# H616 register map
Vendor: Allwinner; Series: H616; File version: 0.1
CPU: other 0, little endian, MPU, no FPU, 0 interrupt priority bits
Registers are 32-bit, read-write, reset 0x0 unless marked. A register's access mark holds for its fields unless they carry their own. Offsets are from the block's base; [hi:lo] are bit positions; lines under a group give offsets from that group; {n}, {i} and the like mark numbered series; 'fields as' and 'values as' point back to an identical list.

## PWM
Base 0x0300A000
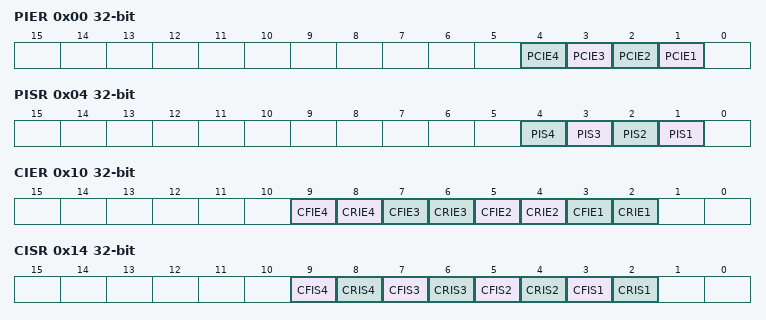
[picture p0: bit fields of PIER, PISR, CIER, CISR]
0x00 PIER — PWM IRQ Enable Register
  [n] PCIE{n} (n=1..4) — PWM Channel {n} Interrupt Enable 0: PWM channel {n} interrupt disable 1: PWM channel {n} interrupt enable
    0=PWM_channel_{n}_interrupt_disable; 1=PWM_channel_{n}_interrupt_enable
0x04 PISR — PWM IRQ Status Register
  [n] PIS{n} write-1-clears (n=1..4) — PWM Channel {n} Interrupt Status When PWM channel {n} counter reaches Entire Cycle Value, this bit is set 1 by hardware. Writing 1 to clear this bit. Reads 0: PWM channel {n} interrupt is not pending. Reads 1: PWM channel {n} interrupt is pending. Writes 0: No effect. Writes 1: Clear PWM channel {n} interrupt status.
0x10 CIER — Capture IRQ Enable Register
  [9] CFIE4 — If the bit is set 1, when capturing channel 4 captures falling edge, it generates a capturing channel 4 pending. 0: Capture channel 4 fall lock interrupt disable 1: Capture channel 4 fall lock interrupt enable
    0=Capture_channel_4_fall_lock_interrupt_disable; 1=Capture_channel_4_fall_lock_interrupt_enable
  [2n] CRIE{n} (n=1..4) — If the bit is set 1, when capturing channel {n} captures rising edge, it generates a capturing channel {n} pending. 0: Capturing channel {n} rise lock interrupt disable 1: Capturing channel {n} rise lock interrupt enable
    0=Capturing_channel_{n}_rise_lock_interrupt_disable; 1=Capturing_channel_{n}_rise_lock_interrupt_enable
  [7] CFIE3 — If the bit is set 1, when capturing channel 3 captures falling edge, it generates a capturing channel 3 pending. 0: Capturing channel 3 fall lock interrupt disable 1: Capturing channel 3 fall lock interrupt enable
    0=Capturing_channel_3_fall_lock_interrupt_disable; 1=Capturing_channel_3_fall_lock_interrupt_enable
  [5] CFIE2 — If the bit is set 1, when capturing channel 2 captures falling edge, it generates a capturing channel 2 pending. 0: Capturing channel 2 fall lock interrupt disable 1: Capturing channel 2 fall lock interrupt enable
    0=Capturing_channel_2_fall_lock_interrupt_disable; 1=Capturing_channel_2_fall_lock_interrupt_enable
  [3] CFIE1 — If the bit is set 1, when capturing channel 1 captures falling edge, it generates a capturing channel 1 pending. 0: Capturing channel 1 fall lock interrupt disable 1: Capturing channel 1 fall lock interrupt enable
    0=Capturing_channel_1_fall_lock_interrupt_disable; 1=Capturing_channel_1_fall_lock_interrupt_enable
0x14 CISR — Capture IRQ Status Register
  [9] CFIS4 write-1-clears — Capturing channel 4 falling lock interrupt status. When capturing channel 4 captures falling edge, if capturing channel 4 fall lock interrupt ( CFIE4 ) is enabled, this bit is set 1 by hardware.Writing 1 to clear this bit. Reads 0: Capturing channel 4 interrupt is not pending. Reads 1: Capturing channel 4 interrupt is pending. Writes 0: No effect. Writes 1: Clear capturing channel 4 interrupt status.
  [8] CRIS4 write-1-clears — Capturing channel 4 rising lock interrupt status. When capturing channel 4 captures rising edge, if capturing channel 4 rise lock interrupt ( CRIE4 ) is enabled, this bit is set 1 by hardware. Writing 1 to clear this bit. Reads 0: Capturing channel 4 interrupt is not pending. Reads 1: Capturing channel 4 interrupt is pending. Writes 0: No effect. Writes 1: Clear capturing channel 4 interrupt status.
  [7] CFIS3 write-1-clears — Capture channel 3 falling lock interrupt status. When capture channel 3 captures falling edge, if capture channel 3 fall lock interrupt ( CFIE3 ) is enabled, this bit is set 1 by hardware.Writing 1 to clear this bit. Reads 0: Capture channel 3 interrupt is not pending. Reads 1: Capture channel 3 interrupt is pending. Writes 0: no effect. Writes 1: Clear capture channel 3 interrupt status.
  [6] CRIS3 write-1-clears — Capture channel 3 rising lock interrupt status. When capture channel 3 captures rising edge, if capture channel 3 rise lock interrupt ( CRIE3 ) is enabled, this bit is set 1 by hardware. Writing 1 to clear this bit. Reads 0: Capture channel 3 interrupt is not pending. Reads 1: Capture channel 3 interrupt is pending. Writes 0: no effect. Writes 1: Clear capture channel 3 interrupt status.
  [5] CFIS2 write-1-clears — Capture channel 2 falling lock interrupt status. When capture channel 2 captures falling edge, if capture channel 2 fall lock interrupt ( CFIE2 ) is enabled, this bit is set 1 by hardware.Writing 1 to clear this bit. Reads 0: Capture channel 2 interrupt is not pending. Reads 1: Capture channel 2 interrupt is pending. Writes 0: no effect. Writes 1: Clear capture channel 2 interrupt status.
  [4] CRIS2 write-1-clears — Capture channel 2 rising lock interrupt status. When capture channel 2 captures rising edge, if capture channel 2 rise lock interrupt ( CRIE2 ) is enabled, this bit is set 1 by hardware. Writing 1 to clear this bit. Reads 0: Capture channel 2 interrupt is not pending. Reads 1: Capture channel 2 interrupt is pending. Writes 0: no effect. Writes 1: Clear capture channel 2 interrupt status.
  [3] CFIS1 write-1-clears — Capture channel 1 falling lock interrupt status. When capture channel 1 captures falling edge, if capture channel 1 fall lock interrupt ( CFIE1 ) is enabled, this bit is set 1 by hardware.Writing 1 to clear this bit. Reads 0: Capture channel 1 interrupt is not pending. Reads 1: Capture channel 1 interrupt is pending. Writes 0: no effect. Writes 1: Clear capture channel 1 interrupt status.
  [2] CRIS1 write-1-clears — Capture channel 1 rising lock interrupt status. When capture channel 1 captures rising edge, if capture channel 1 rise lock interrupt ( CRIE1 ) is enabled, this bit is set 1 by hardware. Writing 1 to clear this bit. Reads 0: Capture channel 1 interrupt is not pending. Reads 1: Capture channel 1 interrupt is pending. Writes 0: no effect. Writes 1: Clear capture channel 1 interrupt status.
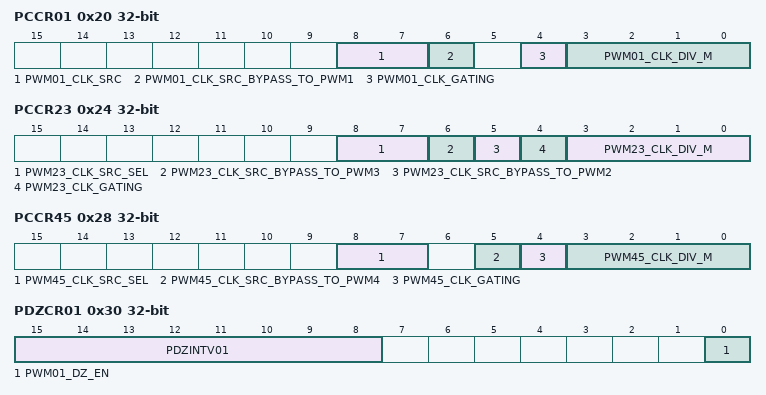
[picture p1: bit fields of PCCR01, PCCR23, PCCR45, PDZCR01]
0x20 PCCR01 — PWM01 Clock Configuration Register
  [8:7] PWM01_CLK_SRC — Select PWM01 clock source 00: OSC24M 01: APB1 Others: Reserved
    0=OSC24M; 1=APB1 (APB1 Others: Reserved)
  [6] PWM01_CLK_SRC_BYPASS_TO_PWM1 — Bypass PWM01 clock source to PWM1 output 0: not bypass 1: bypass
    0=not_bypass; 1=bypass
  [4] PWM01_CLK_GATING — Gating clock for PWM01 0: Mask 1: Pass
    0=Mask; 1=Pass
  [3:0] PWM01_CLK_DIV_M — PWM01 clock divide M 0000: /1 0001: /2 0010: /4 0011: /8 0100: /16 0101: /32 0110: /64 0111: /128 1000: /256 others: Reserved
    0=_slash_1 (/1); 1=_slash_2 (/2); 2=_slash_4 (/4); 3=_slash_8 (/8); 4=_slash_16 (/16); 5=_slash_32 (/32); 6=_slash_64 (/64); 7=_slash_128 (/128); 8=_slash_256 (/256 others: Reserved)
0x24 PCCR23 — PWM23 Clock Configuration Register
  [8:7] PWM23_CLK_SRC_SEL — Select PWM23 clock source 00: OSC24M 01: APB1 Others: Reserved
    0=OSC24M; 1=APB1 (APB1 Others: Reserved)
  [6] PWM23_CLK_SRC_BYPASS_TO_PWM3 — Bypass PWM23 clock source to PWM3 output 0: not bypass 1: bypass
    0=not_bypass; 1=bypass
  [5] PWM23_CLK_SRC_BYPASS_TO_PWM2 — Bypass PWM23 clock source to PWM2 output 0: not bypass 1: bypass
    0=not_bypass; 1=bypass
  [4] PWM23_CLK_GATING — Gating clock for PWM23 0: Mask 1: Pass
    0=Mask; 1=Pass
  [3:0] PWM23_CLK_DIV_M — PWM23 clock divide M 0000: /1 0001: /2 0010: /4 0011: /8 0100: /16 0101: /32 0110: /64 0111: /128 1000: /256 others: /
    0=_slash_1 (/1); 1=_slash_2 (/2); 2=_slash_4 (/4); 3=_slash_8 (/8); 4=_slash_16 (/16); 5=_slash_32 (/32); 6=_slash_64 (/64); 7=_slash_128 (/128); 8=_slash_256 (/256 others: /)
0x28 PCCR45 — PWM45 Clock Configuration Register
  [8:7] PWM45_CLK_SRC_SEL — Select PWM45 clock source 00: OSC24M 01: APB1 Others: Reserved
    0=OSC24M; 1=APB1 (APB1 Others: Reserved)
  [5] PWM45_CLK_SRC_BYPASS_TO_PWM4 — Bypass PWM45 clock source to PWM4 output 0: not bypass 1: bypass
    0=not_bypass; 1=bypass
  [4] PWM45_CLK_GATING — Gating clock for PWM45 0: Mask 1: Pass
    0=Mask; 1=Pass
  [3:0] PWM45_CLK_DIV_M — PWM45 clock divide M 0000: /1 0001: /2 0010: /4 0011: /8 0100: /16 0101: /32 0110: /64 0111: /128 1000: /256 others: /
    values as PCCR23.PWM23_CLK_DIV_M
0x30 PDZCR01 — PWM01 Dead Zone Control Register
  [15:8] PDZINTV01 — PWM01 Dead Zone interval value
  [0] PWM01_DZ_EN — PWM01 Dead Zone enable 0: Dead Zone disable 1: Dead Zone enable
    0=Dead_Zone_disable; 1=Dead_Zone_enable
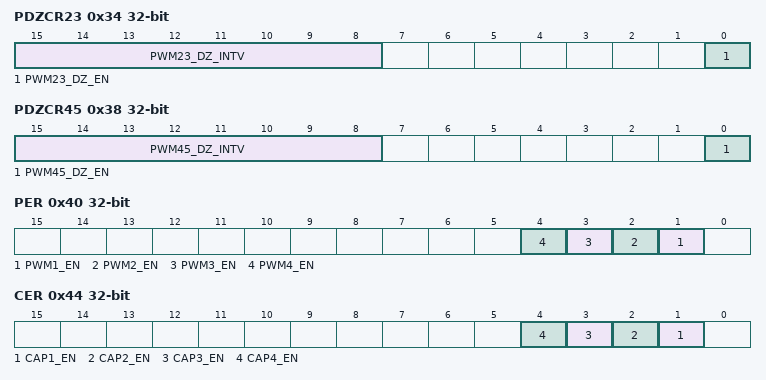
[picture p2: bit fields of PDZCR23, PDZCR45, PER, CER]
0x34 PDZCR23 — PWM23 Dead Zone Control Register
  [15:8] PWM23_DZ_INTV — PWM23 Dead Zone interval value
  [0] PWM23_DZ_EN — PWM23 Dead Zone enable 0: Dead Zone disable 1: Dead Zone enable
    0=Dead_Zone_disable; 1=Dead_Zone_enable
0x38 PDZCR45 — PWM45 Dead Zone Control Register
  [15:8] PWM45_DZ_INTV — PWM45 Dead Zone interval value
  [0] PWM45_DZ_EN — PWM45 Dead Zone enable 0: Dead Zone disable 1: Dead Zone enable
    0=Dead_Zone_disable; 1=Dead_Zone_enable
0x40 PER — PWM Enable Register
  [all] fields
    0=PWM_disable; 1=PWM_enable
  [n] PWM{n}_EN (n=1..4) — When enable PWM, the 16-bit up-counter starts working and PWM channel{n} is permitted to output PWM waveform. 0: PWM disable 1: PWM enable
0x44 CER — Capture Enable Register
  [all] fields
    0=Capture_disable; 1=Capture_enable
  [n] CAP{n}_EN (n=1..4) — When enable capture function, the 16-bit up-counter starts working and capture channel{n} is permitted to capture external falling edge or rising edge. 0: Capture disable 1: Capture enable
{0x60+0x20*i} _N_{i} (i=1..4) group
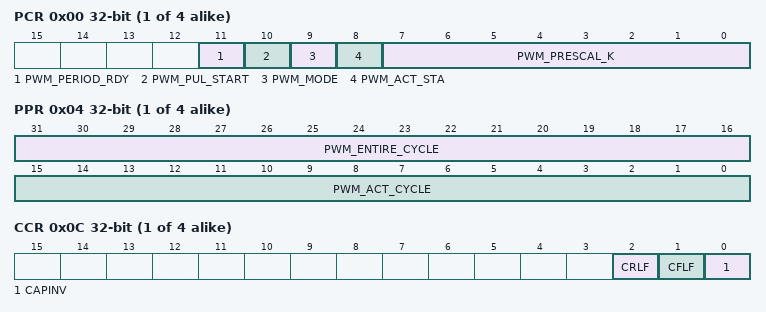
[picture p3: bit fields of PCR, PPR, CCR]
  0x00 PCR — PWM Control Register
    [11] PWM_PERIOD_RDY ro — PWM Period Register Ready 0: PWM period register is ready to write 1: PWM period register is busy
      0=ready (PWM period register is ready to write); 1=busy (PWM period register is busy)
    [10] PWM_PUL_START write-1-sets — PWM Pulse Output Start 0: No effect 1: Output pulse for PWM_CYCLE_NUM+1 After finishing configuration for outputting pulse, set this bit once and then PWM would output waveform. After the waveform is finished, the bit will be cleared automatically.
      0=No_effect; 1=Output pulse for PWM_CYCLE_NUM+1 After finishing configuration for outputting pulse, set this bit once and then PWM would output waveform. After the waveform is finished, the bit will be cleared automatically.
    [9] PWM_MODE — PWM Output Mode Select 0: Cycle mode 1: Pulse mode
      0=Cycle_mode; 1=Pulse_mode
    [8] PWM_ACT_STA — PWM Active State 0: Low Level 1: High Level
      0=Low_Level; 1=High_Level
    [7:0] PWM_PRESCAL_K — PWM pre-scale K, actual pre-scale is (K+1) K = 0, actual pre-scale: 1 K = 1, actual pre-scale: 2 K = 2, actual pre-scale: 3 K = 3, actual pre-scale: 4 ... K = 255, actual pre-scale: 256
  0x04 PPR — PWM Period Register
    [31:16] PWM_ENTIRE_CYCLE — Number of the entire cycles in the PWM clock 0: 1 cycle 1: 2 cycles ... N: N+1 cycles If the register need to be modified dynamically, the PCLK should be faster than the PWM CLK.
    [15:0] PWM_ACT_CYCLE — Number of the active cycles in the PWM clock 0: 0 cycle 1: 1 cycle ... N: N cycles
  0x08 PCNTR — PWM Count Register
    [15:0] PWM_COUNTER_STATUS ro — On PWM output or capture input, reading this register could get the current value of the PWM 16-bit up-counter.
  0x0C CCR — Capture Control Register
    [2] CRLF write-1-clears — When capture channel captures rising edge, the 16-bit up-counter`s current value is latched to CRLR and then this bit is set to 1 by hardware. Write 1 to clear this bit.
    [1] CFLF write-1-clears — When capture channel captures falling edge, the 16-bit up-counter`s current value is latched to CFLR and then this bit is set to 1 by hardware. Write 1 to clear this bit.
    [0] CAPINV — Inversing the signal inputted from capture channel before capture channel's 16-bit counter. 0: not inverse 1: inverse
      0=not_inverse; 1=inverse
  0x10 CRLR — Capture Rise Lock Register
    [15:0] CAPTURE_CHANNEL ro — When capture channel captures rising edge, the 16-bit up-counter`s current value is latched to this register.
  0x14 CFLR — Capture Fall Lock Register
    [15:0] CAPTURING_CHANNEL ro — When the capturing channel captures the falling edge, the current value of the 16-bit up-counter is latched to the register.
